# R7FA8D1BH register map
Vendor: Renesas; Series: RA8; File version: 1.2
CPU: CM85 r0p0, little endian, MPU, FPU, VTOR, 4 interrupt priority bits
Registers are 32-bit, read-write, reset 0x0 unless marked. A register's access mark holds for its fields unless they carry their own. Offsets are from the block's base; [hi:lo] are bit positions; {n}, {i} and the like mark numbered series; 'fields as' and 'values as' point back to an identical list.

## GPT320 (part 2 of 2) — General PWM 32-bit Timer 0
Base 0x40322000
Same registers: GPT321 0x40322100, GPT322 0x40322200, GPT323 0x40322300, GPT324 0x40322400, GPT325 0x40322500, GPT326 0x40322600, GPT327 0x40322700, GPT168 0x40322800, GPT169 0x40322900, GPT1610 0x40322A00, GPT1611 0x40322B00, GPT1612 0x40322C00, GPT1613 0x40322D00, GPT{n}_NS {0x5030E000+0x100*n} (n=320..327), GPT168_NS 0x50322800, GPT169_NS 0x50322900, GPT1610_NS 0x50322A00, GPT1611_NS 0x50322B00, GPT1612_NS 0x50322C00, GPT1613_NS 0x50322D00
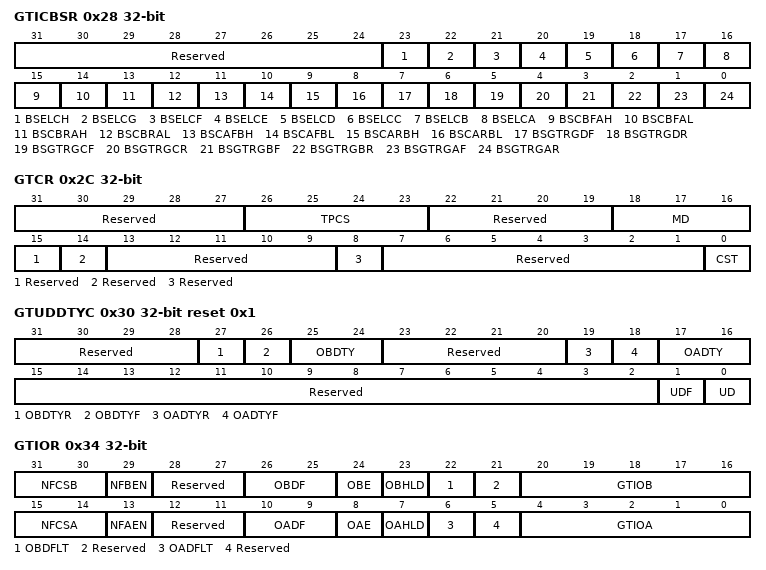
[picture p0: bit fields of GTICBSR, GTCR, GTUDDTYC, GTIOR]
0x28 GTICBSR — General PWM Timer Input Capture Source Select Register B
  [31:24] Reserved — These bits are read as 00000000. The write value should be 00000000.
  [23] BSELCH — ELC_GPTH Event Source GTCCRB Input Capture Enable
    0=Disable GTCCRB input capture on ELC_GPTH input; 1=Enable GTCCRB input capture on ELC_GPTH input
  [22] BSELCG — ELC_GPTG Event Source GTCCRB Input Capture Enable
    0=Disable GTCCRB input capture on ELC_GPTG input; 1=Enable GTCCRB input capture on ELC_GPTG input
  [21] BSELCF — ELC_GPTF Event Source GTCCRB Input Capture Enable
    0=Disable GTCCRB input capture on ELC_GPTF input; 1=Enable GTCCRB input capture on ELC_GPTF input
  [20] BSELCE — ELC_GPTE Event Source GTCCRB Input Capture Enable
    0=Disable GTCCRB input capture on ELC_GPTE input; 1=Enable GTCCRB input capture on ELC_GPTE input
  [19] BSELCD — ELC_GPTD Event Source GTCCRB Input Capture Enable
    0=Disable GTCCRB input capture on ELC_GPTD input; 1=Enable GTCCRB input capture on ELC_GPTD input
  [18] BSELCC — ELC_GPTC Event Source GTCCRB Input Capture Enable
    0=Disable GTCCRB input capture on ELC_GPTC input; 1=Enable GTCCRB input capture on ELC_GPTC input
  [17] BSELCB — ELC_GPTB Event Source GTCCRB Input Capture Enable
    0=Disable GTCCRB input capture on ELC_GPTB input; 1=Enable GTCCRB input capture on ELC_GPTB input
  [16] BSELCA — ELC_GPTA Event Source GTCCRB Input Capture Enable
    0=Disable GTCCRB input capture on ELC_GPTA input; 1=Enable GTCCRB input capture on ELC_GPTA input
  [15] BSCBFAH — GTIOCB Pin Falling Input during GTIOCA Value High Source GTCCRB Input Capture Enable
    0=Disable GTCCRB input capture on the falling edge of GTIOCB input when GTIOCA input is 1; 1=Enable GTCCRB input capture on the falling edge of GTIOCB input when GTIOCA input is 1
  [14] BSCBFAL — GTIOCB Pin Falling Input during GTIOCA Value Low Source GTCCRB Input Capture Enable
    0=Disable GTCCRB input capture on the falling edge of GTIOCB input when GTIOCA input is 0; 1=Enable GTCCRB input capture on the falling edge of GTIOCB input when GTIOCA input is 0
  [13] BSCBRAH — GTIOCB Pin Rising Input during GTIOCA Value High Source GTCCRB Input Capture Enable
    0=Disable GTCCRB input capture on the rising edge of GTIOCB input when GTIOCA input is 1; 1=Enable GTCCRB input capture on the rising edge of GTIOCB input when GTIOCA input is 1
  [12] BSCBRAL — GTIOCB Pin Rising Input during GTIOCA Value Low Source GTCCRB Input Capture Enable
    0=Disable GTCCRB input capture on the rising edge of GTIOCB input when GTIOCA input is 0; 1=Enable GTCCRB input capture on the rising edge of GTIOCB input when GTIOCA input is 0
  [11] BSCAFBH — GTIOCA Pin Falling Input during GTIOCB Value High Source GTCCRB Input Capture Enable
    0=Disable GTCCRB input capture on the falling edge of GTIOCA input when GTIOCB input is 1; 1=Enable GTCCRB input capture on the falling edge of GTIOCA input when GTIOCB input is 1
  [10] BSCAFBL — GTIOCA Pin Falling Input during GTIOCB Value Low Source GTCCRB Input Capture Enable
    0=Disable GTCCRB input capture on the falling edge of GTIOCA input when GTIOCB input is 0; 1=Enable GTCCRB input capture on the falling edge of GTIOCA input when GTIOCB input is 0
  [9] BSCARBH — GTIOCA Pin Rising Input during GTIOCB Value High Source GTCCRB Input Capture Enable
    0=Disable GTCCRB input capture on the rising edge of GTIOCA input when GTIOCB input is 1; 1=Enable GTCCRB input capture on the rising edge of GTIOCA input when GTIOCB input is 1
  [8] BSCARBL — GTIOCA Pin Rising Input during GTIOCB Value Low Source GTCCRB Input Capture Enable
    0=Disable GTCCRB input capture on the rising edge of GTIOCA input when GTIOCB input is 0; 1=Enable GTCCRB input capture on the rising edge of GTIOCA input when GTIOCB input is 0
  [7] BSGTRGDF — GTETRGD Pin Falling Input Source GTCCRB Input Capture Enable
    0=Disable GTCCRB input capture on the falling edge of GTETRGD input; 1=Enable GTCCRB input capture on the falling edge of GTETRGD input
  [6] BSGTRGDR — GTETRGD Pin Rising Input Source GTCCRB Input Capture Enable
    0=Disable GTCCRB input capture on the rising edge of GTETRGD input; 1=Enable GTCCRB input capture on the rising edge of GTETRGD input
  [5] BSGTRGCF — GTETRGC Pin Falling Input Source GTCCRB Input Capture Enable
    0=Disable GTCCRB input capture on the falling edge of GTETRGC input; 1=Enable GTCCRB input capture on the falling edge of GTETRGC input
  [4] BSGTRGCR — GTETRGC Pin Rising Input Source GTCCRB Input Capture Enable
    0=Disable GTCCRB input capture on the rising edge of GTETRGC input; 1=Enable GTCCRB input capture on the rising edge of GTETRGC input
  [3] BSGTRGBF — GTETRGB Pin Falling Input Source GTCCRB Input Capture Enable
    0=Disable GTCCRB input capture on the falling edge of GTETRGB input; 1=Enable GTCCRB input capture on the falling edge of GTETRGB input
  [2] BSGTRGBR — GTETRGB Pin Rising Input Source GTCCRB Input Capture Enable
    0=Disable GTCCRB input capture on the rising edge of GTETRGB input; 1=Enable GTCCRB input capture on the rising edge of GTETRGB input
  [1] BSGTRGAF — GTETRGA Pin Falling Input Source GTCCRB Input Capture Enable
    0=Disable GTCCRB input capture on the falling edge of GTETRGA input; 1=Enable GTCCRB input capture on the falling edge of GTETRGA input
  [0] BSGTRGAR — GTETRGA Pin Rising Input Source GTCCRB Input Capture Enable
    0=Disable GTCCRB input capture on the rising edge of GTETRGA input; 1=Enable GTCCRB input capture on the rising edge of GTETRGA input
0x2C GTCR — General PWM Timer Control Register
  [31:27] Reserved — These bits are read as 00000. The write value should be 00000.
  [26:23] TPCS — Timer Prescaler Select
    0=PCLKGPTnPCLKC/1; 1=PCLKGPTnPCLKC/2; 2=PCLKGPTnPCLKC/4; 3=PCLKGPTnPCLKC/8; 4=PCLKGPTnPCLKC/16; 5=PCLKGPTnPCLKC/32; 6=PCLKGPTnPCLKC/64; 7=Setting prohibited(PCLKGPTn); 8=PCLKGPTnPCLKC/256; 9=Setting prohibited(PCLKGPTn); 10=PCLKGPTnPCLKC/1024; 11=Setting prohibited(PCLKGPTn); 12=GTETRGA (via the POEG); 13=GTETRGB (via the POEG); 14=GTETRGC (via the POEG); 15=GTETRGD (via the POEG)
  [22:19] Reserved — These bits are read as 0000. The write value should be 0000.
  [18:16] MD — Mode Select
    0=Saw-wave PWM mode (single buffer or double buffer possible); 1=Saw-wave one-shot pulse mode (fixed buffer operation); 2=Setting prohibited; 3=Setting prohibited; 4=Triangle-wave PWM mode 1 (32-bit transfer at crest) (single buffer or double buffer possible); 5=Triangle-wave PWM mode 2 (32-bit transfer at crest and trough) (single buffer or double buffer possible); 6=Triangle-wave PWM mode 3 (64-bit transfer at trough) fixed buffer operation); 7=Setting prohibited
  [15] Reserved — This bit is read as 0. The write value should be 0.
  [14] Reserved — This bit is read as 0. The write value should be 0.
  [13:9] Reserved — These bits are read as 00000. The write value should be 00000.
  [8] Reserved — This bit is read as 0. The write value should be 0.
  [7:1] Reserved — These bits are read as 0000000. The write value should be 0000000.
  [0] CST — Count Start
    0=Count operation is stopped; 1=Count operation is performed
0x30 GTUDDTYC reset 0x1 — General PWM Timer Count Direction and Duty Setting Register
  [31:28] Reserved — These bits are read as 0000. The write value should be 0000.
  [27] OBDTYR — GTIOCB Output Value Selecting after Releasing 0 percent/100 percent Duty Setting
    0=Apply output value set in 0 percent/100 percent duty to GTIOB[3:2] function after releasing 0percent/100percent duty setting; 1=Apply masked compare match output value to GTIOB[3:2] function after releasing 0percent/100percent duty setting
  [26] OBDTYF — Forcible GTIOCB Output Duty Setting
    0=Do not force setting; 1=Force setting
  [25:24] OBDTY — GTIOCB Output Duty Setting
    0=GTIOCB pin duty is depend on compare match; 1=GTIOCB pin duty is depend on compare match; 2=GTIOCB pin duty 0percent; 3=GTIOCB pin duty 100percent
  [23:20] Reserved — These bits are read as 0000. The write value should be 0000.
  [19] OADTYR — GTIOCA Output Value Selecting after Releasing 0 percent/100 percent Duty Setting
    0=Apply output value set in 0 percent/100 percent duty to GTIOA[3:2] function after releasing 0 percent/100 percent duty setting; 1=Apply masked compare match output value to GTIOA[3:2] function after releasing 0 percent/100 percent duty setting
  [18] OADTYF — Forcible GTIOCA Output Duty Setting
    0=Do not force setting; 1=Force setting
  [17:16] OADTY — GTIOCA Output Duty Setting
    0=GTIOCA pin duty is depend on compare match; 1=GTIOCA pin duty is depend on compare match; 2=GTIOCA pin duty 0 percent; 3=GTIOCA pin duty 100 percent
  [15:2] Reserved — These bits are read as 00000000000000. The write value should be 00000000000000.
  [1] UDF — Forcible Count Direction Setting
    0=Do not force setting; 1=Force setting
  [0] UD — Count Direction Setting
    0=Count down on GTCNT; 1=Counts up on GTCNT
0x34 GTIOR — General PWM Timer I/O Control Register
  [31:30] NFCSB — Noise Filter B Sampling Clock Select
    0=PCLKGPTn/1; 1=PCLKGPTn/4; 2=PCLKGPTn/16; 3=PCLKGPTn/64
  [29] NFBEN — Noise Filter B Enable
    0=Disable noise filter for GTIOCB pin; 1=Enable noise filter for GTIOCB pin
  [28:27] Reserved — These bits are read as 00. The write value should be 00.
  [26:25] OBDF — GTIOCB Pin Disable Value Setting
    0=Prohibit output disable; 1=Set GTIOCB pin to Hi-Z on output disable; 2=Set GTIOCB pin to 0 on output disable; 3=Set GTIOCB pin to 1 on output disable
  [24] OBE — GTIOCB Pin Output Enable
    0=Disable output; 1=Enable output
  [23] OBHLD — GTIOCB Pin Output Setting at the Start/Stop Count
    0=Set GTIOCB pin output level on counting start and stop based on the register setting; 1=Retain GTIOCB pin output level on counting start and stop
  [22] OBDFLT — GTIOCB Pin Output Value Setting at the Count Stop
    0=Output low on GTIOCB pin when counting stops; 1=Output high on GTIOCB pin when counting stops
  [21] Reserved — This bit is read as 0. The write value should be 0.
  [20:16] GTIOB — GTIOCB Pin Function Select
    0=Initial output is Low. Output retained at cycle end. Output retained at GTCCRB compare match.; 1=Initial output is Low. Output retained at cycle end. Low output at GTCCRB compare match.; 2=Initial output is Low. Output retained at cycle end. High output at GTCCRB compare match.; 3=Initial output is Low. Output retained at cycle end. Output toggled at GTCCRB compare match.; 4=Initial output is Low. Low output at cycle end. Output retained at GTCCRB compare match.; 5=Initial output is Low. Low output at cycle end. Low output at GTCCRB compare match.; 6=Initial output is Low. Low output at cycle end. High output at GTCCRB compare match.; 7=Initial output is Low. Low output at cycle end. Output toggled at GTCCRB compare match.; 8=Initial output is Low. High output at cycle end. Output retained at GTCCRB compare match.; 9=Initial output is Low. High output at cycle end. Low output at GTCCRB compare match.; 10=Initial output is Low. High output at cycle end. High output at GTCCRB compare match.; 11=Initial output is Low. High output at cycle end. Output toggled at GTCCRB compare match.; 12=Initial output is Low. Output toggled at cycle end. Output retained at GTCCRB compare match.; 13=Initial output is Low. Output toggled at cycle end. Low output at GTCCRB compare match.; 14=Initial output is Low. Output toggled at cycle end. High output at GTCCRB compare match.; 15=Initial output is Low. Output toggled at cycle end. Output toggled at GTCCRB compare match.; 16=Initial output is High. Output retained at cycle end. Output retained at GTCCRB compare match.; 17=Initial output is High. Output retained at cycle end. Low output at GTCCRB compare match.; 18=Initial output is High. Output retained at cycle end. High output at GTCCRB compare match.; 19=Initial output is High. Output retained at cycle end. Output toggled at GTCCRB compare match.; 20=Initial output is High. Low output at cycle end. Output retained at GTCCRB compare match.; 21=Initial output is High. Low output at cycle end. Low output at GTCCRB compare match.; 22=Initial output is High. Low output at cycle end. High output at GTCCRB compare match.; 23=Initial output is High. Low output at cycle end. Output toggled at GTCCRB compare match.; 24=Initial output is High. High output at cycle end. Output retained at GTCCRB compare match.; 25=Initial output is High. High output at cycle end. Low output at GTCCRB compare match.; 26=Initial output is High. High output at cycle end. High output at GTCCRB compare match.; 27=Initial output is High. High output at cycle end. Output toggled at GTCCRB compare match.; 28=Initial output is High. Output toggled at cycle end. Output retained at GTCCRB compare match.; 29=Initial output is High. Output toggled at cycle end. Low output at GTCCRB compare match.; 30=Initial output is High. Output toggled at cycle end. High output at GTCCRB compare match.; 31=Initial output is High. Output toggled at cycle end. Output toggled at GTCCRB compare match.
  [15:14] NFCSA — Noise Filter A Sampling Clock Select
    0=PCLKGPTn/1; 1=PCLKGPTn/4; 2=PCLKGPTn/16; 3=PCLKGPTn/64
  [13] NFAEN — Noise Filter A Enable
    0=Disable noise filter for GTIOCA pin; 1=Enable noise filter for GTIOCA pin
  [12:11] Reserved — These bits are read as 00. The write value should be 00.
  [10:9] OADF — GTIOCA Pin Disable Value Setting
    0=Prohibit output disable; 1=Set GTIOCA pin to Hi-Z on output disable; 2=Set GTIOCA pin to 0 on output disable; 3=Set GTIOCA pin to 1 on output disable
  [8] OAE — GTIOCA Pin Output Enable
    0=Disable output; 1=Enable output
  [7] OAHLD — GTIOCA Pin Output Setting at the Start/Stop Count
    0=Set GTIOCA pin output level on counting start and stop based on the register setting; 1=Retain GTIOCA pin output level on counting start and stop
  [6] OADFLT — GTIOCA Pin Output Value Setting at the Count Stop
    0=Output low on GTIOCA pin when counting stops; 1=Output high on GTIOCA pin when counting stops
  [5] Reserved — This bit is read as 0. The write value should be 0.
  [4:0] GTIOA — GTIOCA Pin Function Select
    0=Initial output is Low. Output retained at cycle end. Output retained at GTCCRA compare match.; 1=Initial output is Low. Output retained at cycle end. Low output at GTCCRA compare match.; 2=Initial output is Low. Output retained at cycle end. High output at GTCCRA compare match.; 3=Initial output is Low. Output retained at cycle end. Output toggled at GTCCRA compare match.; 4=Initial output is Low. Low output at cycle end. Output retained at GTCCRA compare match.; 5=Initial output is Low. Low output at cycle end. Low output at GTCCRA compare match.; 6=Initial output is Low. Low output at cycle end. High output at GTCCRA compare match.; 7=Initial output is Low. Low output at cycle end. Output toggled at GTCCRA compare match.; 8=Initial output is Low. High output at cycle end. Output retained at GTCCRA compare match.; 9=Initial output is Low. High output at cycle end. Low output at GTCCRA compare match.; 10=Initial output is Low. High output at cycle end. High output at GTCCRA compare match.; 11=Initial output is Low. High output at cycle end. Output toggled at GTCCRA compare match.; 12=Initial output is Low. Output toggled at cycle end. Output retained at GTCCRA compare match.; 13=Initial output is Low. Output toggled at cycle end. Low output at GTCCRA compare match.; 14=Initial output is Low. Output toggled at cycle end. High output at GTCCRA compare match.; 15=Initial output is Low. Output toggled at cycle end. Output toggled at GTCCRA compare match.; 16=Initial output is High. Output retained at cycle end. Output retained at GTCCRA compare match.; 17=Initial output is High. Output retained at cycle end. Low output at GTCCRA compare match.; 18=Initial output is High. Output retained at cycle end. High output at GTCCRA compare match.; 19=Initial output is High. Output retained at cycle end. Output toggled at GTCCRA compare match.; 20=Initial output is High. Low output at cycle end. Output retained at GTCCRA compare match.; 21=Initial output is High. Low output at cycle end. Low output at GTCCRA compare match.; 22=Initial output is High. Low output at cycle end. High output at GTCCRA compare match.; 23=Initial output is High. Low output at cycle end. Output toggled at GTCCRA compare match.; 24=Initial output is High. High output at cycle end. Output retained at GTCCRA compare match.; 25=Initial output is High. High output at cycle end. Low output at GTCCRA compare match.; 26=Initial output is High. High output at cycle end. High output at GTCCRA compare match.; 27=Initial output is High. High output at cycle end. Output toggled at GTCCRA compare match.; 28=Initial output is High. Output toggled at cycle end. Output retained at GTCCRA compare match.; 29=Initial output is High. Output toggled at cycle end. Low output at GTCCRA compare match.; 30=Initial output is High. Output toggled at cycle end. High output at GTCCRA compare match.; 31=Initial output is High. Output toggled at cycle end. Output toggled at GTCCRA compare match.
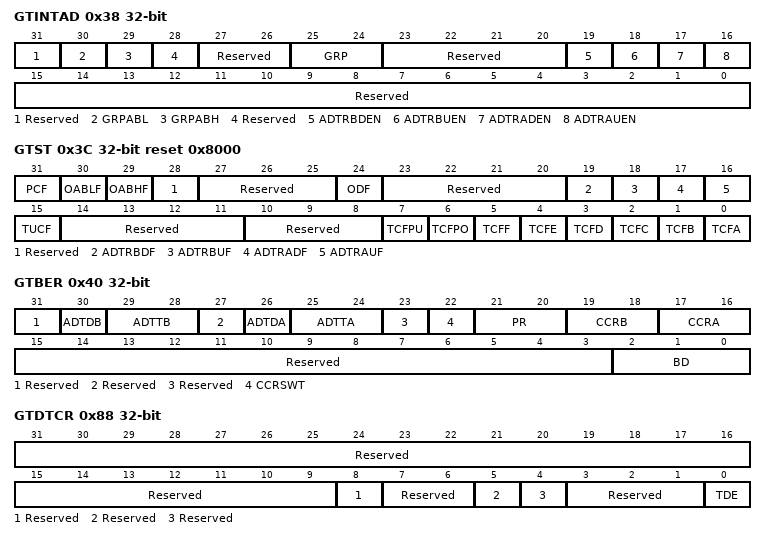
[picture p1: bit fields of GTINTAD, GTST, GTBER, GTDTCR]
0x38 GTINTAD — General PWM Timer Interrupt Output Setting Register
  [31] Reserved — This bit is read as 0. The write value should be 0.
  [30] GRPABL — Same Time Output Level Low Disable Request Enable
    0=Disable same time output level low disable request; 1=Enable same time output level low disable request
  [29] GRPABH — Same Time Output Level High Disable Request Enable
    0=Disable same time output level high disable request; 1=Enable same time output level high disable request
  [28] Reserved — This bit is read as 0. The write value should be 0.
  [27:26] Reserved — These bits are read as 00. The write value should be 00.
  [25:24] GRP — Output Disable Source Select
    0=Select Group A output disable request; 1=Select Group B output disable request; 2=Select Group C output disable request; 3=Select Group D output disable request
  [23:20] Reserved — These bits are read as 0000. The write value should be 0000.
  [19] ADTRBDEN — GTADTRB Compare Match (Down-Counting) A/D Converter Start Request Interrupt Enable
    0=Disable A/D converter start request; 1=Enable A/D converter start request
  [18] ADTRBUEN — GTADTRB Compare Match (Up-Counting) A/D Converter Start Request Interrupt Enable
    values as ADTRBDEN
  [17] ADTRADEN — GTADTRA Compare Match (Down-Counting) A/D Converter Start Request Interrupt Enable
    values as ADTRBDEN
  [16] ADTRAUEN — GTADTRA Compare Match (Up-Counting) A/D Converter Start Request Interrupt Enable
    values as ADTRBDEN
  [15:0] Reserved — These bits are read as 0000000000000000. The write value should be 0000000000000000.
0x3C GTST reset 0x8000 — General PWM Timer Status Register
  [31] PCF — Period Count Function Finish Flag
    0=No period count function finish has occurred; 1=A period count function finish has occurred
  [30] OABLF ro — Same Time Output Level Low Disable Request Enable
    0=GTIOCA pin and GTIOCB pin don't output 0 at the same time; 1=GTIOCA pin and GTIOCB pin output 0 at the same time
  [29] OABHF ro — Same Time Output Level High Disable Request Enable
    0=GTIOCA pin and GTIOCB pin don't output 1 at the same time; 1=GTIOCA pin and GTIOCB pin output 1 at the same time
  [28] Reserved — This bit is read as 0. The write value should be 0.
  [27:25] Reserved — These bits are read as 000. The write value should be 000.
  [24] ODF ro — Output Disable Flag
    0=No output disable request is generated; 1=An output disable request is generated
  [23:20] Reserved — These bits are read as 0000. The write value should be 0000.
  [19] ADTRBDF — GTADTRB Register Compare Match(Down-Counting) A/D Converter Start Request Flag
    0=No GTADTRB register compare match has occurred in down-counting; 1=A GTADTRB register compare match has occurred in down-counting
  [18] ADTRBUF — GTADTRB Register Compare Match(Up-Counting) A/D Converter Start Request Flag
    0=No GTADTRB register compare match has occurred in up-counting; 1=A GTADTRB register compare match has occurred in up-counting
  [17] ADTRADF — GTADTRA Register Compare Match(Down-Counting) A/D Converter Start Request Flag
    0=No GTADTRA register compare match has occurred in down-counting; 1=A GTADTRA register compare match has occurred in down-counting
  [16] ADTRAUF — GTADTRA Register Compare Match(Up-Counting) A/D Converter Start Request Flag
    0=No GTADTRA register compare match has occurred in up-counting; 1=A GTADTRA register compare match has occurred in up-counting
  [15] TUCF ro — Count Direction Flag
    0=GTCNT counter is counting down; 1=GTCNT counter is counting up
  [14:11] Reserved — These bits are read as 0000. The write value should be 0000.
  [10:8] Reserved — These bits are read as 000. The write value should be 000.
  [7] TCFPU — Underflow Flag
    0=No underflow (trough) has occurred; 1=An underflow (trough) has occurred
  [6] TCFPO — Overflow Flag
    0=No overflow (crest) has occurred; 1=An overflow (crest) has occurred
  [5] TCFF — Input Compare Match Flag F
    0=No compare match of GTCCRF is generated; 1=A compare match of GTCCRF is generated
  [4] TCFE — Input Compare Match Flag E
    0=No compare match of GTCCRE is generated; 1=A compare match of GTCCRE is generated
  [3] TCFD — Input Compare Match Flag D
    0=No compare match of GTCCRD is generated; 1=A compare match of GTCCRD is generated
  [2] TCFC — Input Compare Match Flag C
    0=No compare match of GTCCRC is generated; 1=A compare match of GTCCRC is generated
  [1] TCFB — Input Capture/Compare Match Flag B
    0=No input capture/compare match of GTCCRB is generated; 1=An input capture/compare match of GTCCRB is generated
  [0] TCFA — Input Capture/Compare Match Flag A
    0=No input capture/compare match of GTCCRA is generated; 1=An input capture/compare match of GTCCRA is generated
0x40 GTBER — General PWM Timer Buffer Enable Register
  [31] Reserved — This bit is read as 0. The write value should be 0.
  [30] ADTDB — GTADTRB Double Buffer Operation
    0=Single buffer operation (GTADTBRB --> GTADTRB); 1=Double buffer operation (GTADTDBRB --> GTADTBRB --> GTADTDRB)
  [29:28] ADTTB — GTADTRB Buffer Transfer Timing Select in the Triangle wavesNOTE: In the Saw waves, values other than 0 0: Transfer at an underflow (in down-counting) or overflow (in up-counting) is performed.
    0=No transfer; 1=Transfer at crest; 2=Transfer at trough; 3=Transfer at both crest and trough
  [27] Reserved — This bit is read as 0. The write value should be 0.
  [26] ADTDA — GTADTRA Double Buffer Operation
    0=Single buffer operation (GTADTBRA --> GTADTRA); 1=Double buffer operation (GTADTDBRA --> GTADTBRA --> GTADTDRA)
  [25:24] ADTTA — GTADTRA Buffer Transfer Timing Select in the Triangle wavesNOTE: In the Saw waves, values other than 0 0: Transfer at an underflow (in down-counting) or overflow (in up-counting) is performed.
    values as ADTTB
  [23] Reserved — This bit is read as 0. The write value should be 0.
  [22] CCRSWT wo — GTCCRA and GTCCRB Forcible Buffer OperationThis bit is read as 0.
    0=no effect; 1=Forcibly performs buffer transfer of GTCCRA and GTCCRB. This bit automatically returns to 0 after the writing of 1.
  [21:20] PR — GTPR Buffer Operation
    0=Buffer operation is not performed; 1=Buffer operation (GTPBR register to GTPR register); other=others (Setting prohibited)
  [19:18] CCRB — GTCCRB Buffer Operation
    0=Buffer operation is not performed; 1=Single buffer operation (GTCCRB register to GTCCRE register); other=others (Double buffer operation (GTCCRB register to GTCCRE register to GTCCRF register))
  [17:16] CCRA — GTCCRA Buffer Operation
    0=Buffer operation is not performed; 1=Single buffer operation (GTCCRA register to GTCCRC register); other=others (Double buffer operation (GTCCRA register to GTCCRC register to GTCCRD register))
  [15:3] Reserved — These bits are read as 0000000000000. The write value should be 0000000000000.
  [2:0] BD — BD[2]: GTADTR Buffer Operation DisableBD[1]: GTPR Buffer Operation DisableBD[0]: GTCCR Buffer Operation Disable
    0=Enable buffer operation; 1=Disable buffer operation
0x48 GTCNT — General PWM Timer Counter
  [31:0] GTCNT — Counter
0x4C GTCCRA reset 0xFFFFFFFF — General PWM Timer Compare Capture Register A
  [31:0] GTCCRA — Compare Capture Register A
0x50 GTCCRB reset 0xFFFFFFFF — General PWM Timer Compare Capture Register B
  [31:0] GTCCRB — Compare Capture Register B
0x54 GTCCRC reset 0xFFFFFFFF — General PWM Timer Compare Capture Register C
  [31:0] GTCCRC — Compare Capture Register C
0x58 GTCCRE reset 0xFFFFFFFF — General PWM Timer Compare Capture Register E
  [31:0] GTCCRE — Compare Capture Register E
0x5C GTCCRD reset 0xFFFFFFFF — General PWM Timer Compare Capture Register D
  [31:0] GTCCRD — Compare Capture Register D
0x60 GTCCRF reset 0xFFFFFFFF — General PWM Timer Compare Capture Register F
  [31:0] GTCCRF — Compare Capture Register F
0x64 GTPR reset 0xFFFFFFFF — General PWM Timer Cycle Setting Register
  [31:0] GTPR — Cycle Setting Register
0x68 GTPBR reset 0xFFFFFFFF — General PWM Timer Cycle Setting Buffer Register
  [31:0] GTPBR — Cycle Setting Buffer Register
0x70 GTADTRA reset 0xFFFFFFFF — A/D Converter Start Request Timing Register A
0x74 GTADTBRA reset 0xFFFFFFFF — A/D Converter Start Request Timing Buffer Register A
0x78 GTADTDBRA reset 0xFFFFFFFF — A/D Converter Start Request Timing Double-Buffer Register A
0x7C GTADTRB reset 0xFFFFFFFF — A/D Converter Start Request Timing Register B
0x80 GTADTBRB reset 0xFFFFFFFF — A/D Converter Start Request Timing Buffer Register B
0x84 GTADTDBRB reset 0xFFFFFFFF — A/D Converter Start Request Timing Double-Buffer Register B
0x88 GTDTCR — General PWM Timer Dead Time Control Register
  [31:9] Reserved — These bits are read as 00000000000000000000000. The write value should be 00000000000000000000000.
  [8] Reserved — This bit is read as 0. The write value should be 0.
  [7:6] Reserved — These bits are read as 00. The write value should be 00.
  [5] Reserved — This bit is read as 0. The write value should be 0.
  [4] Reserved — This bit is read as 0. The write value should be 0.
  [3:1] Reserved — These bits are read as 000. The write value should be 000.
  [0] TDE — Negative-Phase Waveform Setting
    0=Set GTCCRB without using GTDVU and GTDVD; 1=Use GTDVU and GTDVD to set the compare match value for negative-phase waveform with automatic dead time in GTCCRB
0x8C GTDVU reset 0xFFFFFFFF — General PWM Timer Dead Time Value Register U
  [31:0] GTDVU — Dead Time Value Register U
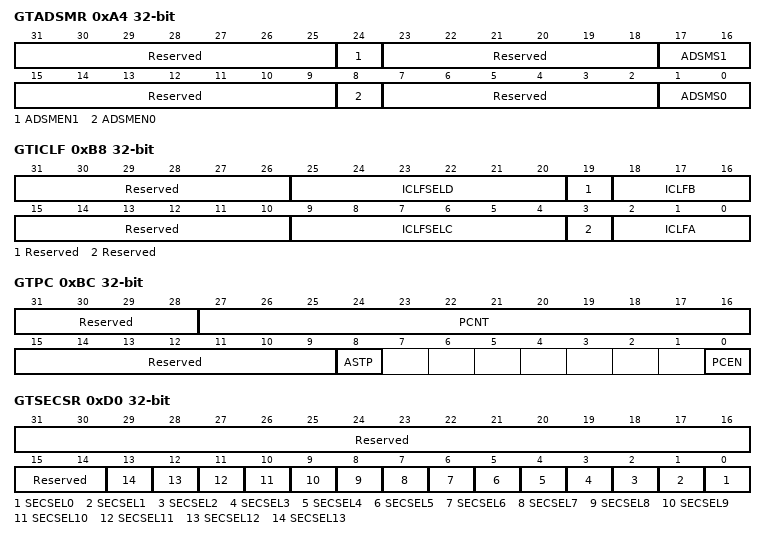
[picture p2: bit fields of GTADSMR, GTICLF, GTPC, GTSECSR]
0xA4 GTADSMR — General PWM Timer A/D Conversion Start Request Signal Monitoring Register
  [31:25] Reserved — These bits are read as 0000000. The write value should be 0000000.
  [24] ADSMEN1 — A/D Conversion Start Request Signal Monitor 1 Output Enabling
    0=Output of A/D conversion start request signal monitor 1 is disabled; 1=Output of A/D conversion start request signal monitor 1 is enabled
  [23:18] Reserved — These bits are read as 000000. The write value should be 000000.
  [17:16] ADSMS1 — A/D Conversion Start Request Signal Monitor 1 Selection
    0=A/D conversion start request signal generated by the GTADTRA register during up-counting; 1=A/D conversion start request signal generated by the GTADTRA register during down-counting; 2=A/D conversion start request signal generated by the GTADTRB register during up-counting; 3=A/D conversion start request signal generated by the GTADTRB register during down-counting
  [15:9] Reserved — These bits are read as 0000000. The write value should be 0000000.
  [8] ADSMEN0 — A/D Conversion Start Request Signal Monitor 0 Output Enabling
    0=Output of A/D conversion start request signal monitor 0 is disabled; 1=Output of A/D conversion start request signal monitor 0 is enabled
  [7:2] Reserved — These bits are read as 000000. The write value should be 000000.
  [1:0] ADSMS0 — A/D Conversion Start Request Signal Monitor 0 Selection
    values as ADSMS1
0xB8 GTICLF — General PWM Timer Inter Channel Logical Operation Function Setting Register
  [31:26] Reserved — These bits are read as 000000. The write value should be 000000.
  [25:20] ICLFSELD — Inter Channel Signal D Select
    0=GTIOC0A; 1=GTIOC0B; 2=GTIOC1A; 3=GTIOC1B; 4=GTIOC2A; 5=GTIOC2B; 6=GTIOC3A; 7=GTIOC3B; 62=GTIOC31A; 63=GTIOC31B
  [19] Reserved — This bit is read as 0. The write value should be 0.
  [18:16] ICLFB — GTIOCnB Output Logical Operation Function Select
    0=B (no delay); 1=NOT B (no delay); 2=D (1PCLKGPTn delay); 3=NOT D (1PCLKGPTn delay); 4=B AND D (1PCLKGPTn delay); 5=B OR D (1PCLKGPTn delay); 6=B EXOR D (1PCLKGPTn delay); 7=B NOR D (1PCLKGPTn delay)
  [15:10] Reserved — These bits are read as 000000. The write value should be 000000.
  [9:4] ICLFSELC — Inter Channel Signal C Select
    values as ICLFSELD
  [3] Reserved — This bit is read as 0. The write value should be 0.
  [2:0] ICLFA — GTIOCnA Output Logical Operation Function Select
    0=A (no delay); 1=NOT A (no delay); 2=C (1PCLKGPTn delay); 3=NOT C (1PCLKGPTn delay); 4=A AND C (1PCLKGPTndelay); 5=A OR C (1PCLKGPTndelay); 6=A EXOR C (1PCLKGPTn delay); 7=A NOR C (1PCLKGPTndelay)
0xBC GTPC — General PWM Timer Period Count Register
  [31:28] Reserved — These bits are read as 0000. The write value should be 0000.
  [27:16] PCNT — Period Counter
  [15:9] Reserved — These bits are read as 0000000. The write value should be 0000000.
  [8] ASTP — Automatic Stop Function Enable
    0=Automatic stop function is disabled; 1=Automatic stop function is enabled
  [0] PCEN — Period Count Function Enable
    0=Period count function is disabled; 1=Period count function is enabled
0xD0 GTSECSR — General PWM Timer Operation Enable Bit Simultaneous Control Channel Select Register
  [31:16] Reserved — These bits are read as 0000000000000000. The write value should be 0000000000000000.
  [15:14] Reserved — These bits are read as 00. The write value should be 00.
  [n] SECSEL{n} (n=0..13) — Channel {n} Operation Enable BitSimultaneous Control Channel Select
    0=Disable simultaneous control; 1=Enable simultaneous control
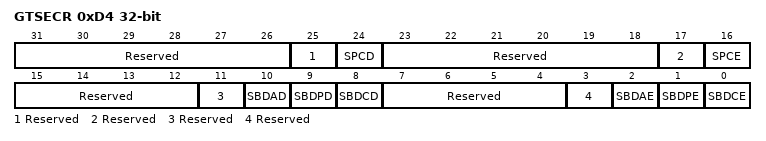
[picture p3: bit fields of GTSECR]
0xD4 GTSECR — General PWM Timer Operation Enable Bit Simultaneous Control Register
  [31:26] Reserved — These bits are read as 000000. The write value should be 000000.
  [25] Reserved — This bit is read as 0. The write value should be 0.
  [24] SPCD — Period Count Function Simultaneous Disable
    0=Disable simultaneous disabling period count function; 1=Disable period count function simultaneously
  [23:18] Reserved — These bits are read as 000000. The write value should be 000000.
  [17] Reserved — This bit is read as 0. The write value should be 0.
  [16] SPCE — Period Count Function Simultaneous Enable
    0=Disable simultaneous enabling period count function; 1=Enable period count function simultaneously
  [15:12] Reserved — These bits are read as 0000. The write value should be 0000.
  [11] Reserved — This bit is read as 0. The write value should be 0.
  [10] SBDAD — GTADTR Register Buffer Operation Simultaneous Disable
    0=Disable simultaneous disabling GTADTR buffer operations; 1=Disable GTADTR register buffer operations simultaneously
  [9] SBDPD — GTPR Register Buffer Operation Simultaneous Disable
    0=Disable simultaneous disabling GTPR buffer operations; 1=Disable GTPR register buffer operations simultaneously
  [8] SBDCD — GTCCR Register Buffer Operation Simultaneous Disable
    0=Disable simultaneous disabling GTCCR buffer operations; 1=Disable GTCCR register buffer operations simultaneously
  [7:4] Reserved — These bits are read as 0000. The write value should be 0000.
  [3] Reserved — This bit is read as 0. The write value should be 0.
  [2] SBDAE — GTADTR Register Buffer Operation Simultaneous Enable
    0=Disable simultaneous enabling GTADTR buffer operations; 1=Enable GTADTR register buffer operations simultaneously
  [1] SBDPE — GTPR Register Buffer Operation Simultaneous Enable
    0=Disable simultaneous enabling GTPR buffer operations; 1=Enable GTPR register buffer operations simultaneously
  [0] SBDCE — GTCCR Register Buffer Operation Simultaneous Enable
    0=Disable simultaneous enabling GTCCR buffer operations; 1=Enable GTCCR register buffer operations simultaneously
